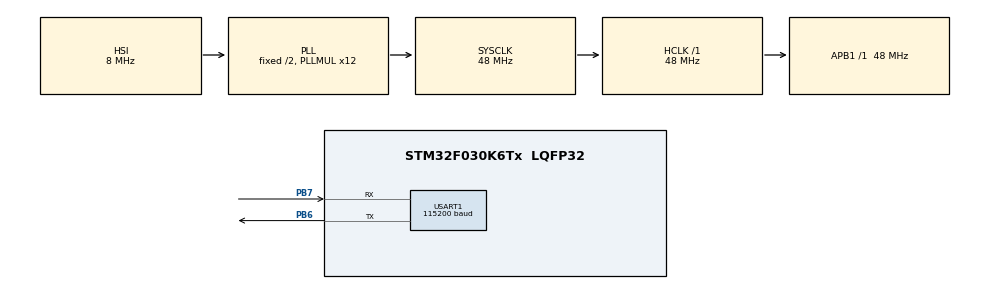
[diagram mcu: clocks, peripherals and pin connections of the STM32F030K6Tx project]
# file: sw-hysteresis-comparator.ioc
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Mcu.Family=STM32F0
Mcu.Name=STM32F030K6Tx
Mcu.Package=LQFP32
PB6.Mode=Asynchronous
PB6.Signal=USART1_TX
PB7.Mode=Asynchronous
PB7.Signal=USART1_RX
ProjectManager.HeapSize=0x200
ProjectManager.StackSize=0x400
ProjectManager.TargetToolchain=MDK-ARM V5
RCC.AHBFreq_Value=48000000
RCC.APB1Freq_Value=48000000
RCC.APB1TimFreq_Value=48000000
RCC.FLatency=FLASH_LATENCY_1
RCC.HCLKFreq_Value=48000000
RCC.PLLMUL=RCC_PLL_MUL12
RCC.SYSCLKFreq_VALUE=48000000
RCC.SYSCLKSource=RCC_SYSCLKSOURCE_PLLCLK
USART1.BaudRate=115200
USART1.VirtualMode-Asynchronous=VM_ASYNC
board=custom

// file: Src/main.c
/* USER CODE BEGIN Header */

/* USER CODE END Header */

#include "main.h"

/* USER CODE BEGIN Includes */
#include "stdio-port-stm32.h"
#include "utility.h"
#include "hysteresis.h"
/* USER CODE END Includes */

UART_HandleTypeDef huart1;

/* USER CODE BEGIN PV */

hysteresis_t hys_cpm;

/* USER CODE END PV */

void SystemClock_Config(void);
static void MX_GPIO_Init(void);
static void MX_USART1_UART_Init(void);

int main(void)
{

  /* MCU Configuration--------------------------------------------------------*/

  /* Reset of all peripherals, Initializes the Flash interface and the Systick. */
  HAL_Init();

  /* Configure the system clock */
  SystemClock_Config();

  /* Initialize all configured peripherals */
  MX_GPIO_Init();
  MX_USART1_UART_Init();
  /* USER CODE BEGIN 2 */
  hysteresis_create(&hys_cpm, 500, 400); /* 500 - compare value, 400 - time delay in ms*/

  /* USER CODE END 2 */

  /* Infinite loop */
  /* USER CODE BEGIN WHILE */
  int32_t signal = 500;
  int32_t noise_signal = 0;
  bool inc_dec = false;

  bool normal_compare;
  uint32_t time;
  uint32_t gen_time;
  uint32_t print_time;
  uint32_t noise_inject_time;
  while (1)
  {
    time = HAL_GetTick();
    /* signal generator */
    if (time - gen_time > 1000)
    {
      gen_time = time;

      if (signal < 400) /* Mininum siganl applitude */
      {
        inc_dec = true;
      }
      if (signal > 600) /* Mininum siganl applitude */
      {
        inc_dec = false;
      }

      if (inc_dec)
      {
        signal += 50;
      }
      else
      {
        signal -= 50;
      }
    }

    /* Noise signal injection */
    if (time - noise_inject_time > 50)
    {
      noise_inject_time = time;
      noise_signal = signal + random(-100, 100);
    }

    /* convetional method data comapare */
    if (noise_signal > 500)
    {
      normal_compare = true;
    }
    else
    {
      normal_compare = false;
    }

    /* Hysteresis comapare */
    hysteresis_compare(&hys_cpm, noise_signal);

    /* print signal */
    if (time - print_time > 50)
    {
      print_time = time;
      printf("$%d %d %d;", noise_signal, normal_compare * 100,
             -110 + hys_cpm.hys_state * 100);
      /* Value add and multiply for shift signal in plot*/
    }
    /* USER CODE END WHILE */

  }
}

void SystemClock_Config(void)
{
  RCC_OscInitTypeDef RCC_OscInitStruct = { 0 };
  RCC_ClkInitTypeDef RCC_ClkInitStruct = { 0 };
  RCC_PeriphCLKInitTypeDef PeriphClkInit = { 0 };

  /**Initializes the CPU, AHB and APB busses clocks
   */
  RCC_OscInitStruct.OscillatorType = RCC_OSCILLATORTYPE_HSI;
  RCC_OscInitStruct.HSIState = RCC_HSI_ON;
  RCC_OscInitStruct.HSICalibrationValue = RCC_HSICALIBRATION_DEFAULT;
  RCC_OscInitStruct.PLL.PLLState = RCC_PLL_ON;
  RCC_OscInitStruct.PLL.PLLSource = RCC_PLLSOURCE_HSI;
  RCC_OscInitStruct.PLL.PLLMUL = RCC_PLL_MUL12;
  RCC_OscInitStruct.PLL.PREDIV = RCC_PREDIV_DIV1;
  if (HAL_RCC_OscConfig(&RCC_OscInitStruct) != HAL_OK)
  {
    Error_Handler();
  }
  /**Initializes the CPU, AHB and APB busses clocks
   */
  RCC_ClkInitStruct.ClockType = RCC_CLOCKTYPE_HCLK | RCC_CLOCKTYPE_SYSCLK
                                | RCC_CLOCKTYPE_PCLK1;
  RCC_ClkInitStruct.SYSCLKSource = RCC_SYSCLKSOURCE_PLLCLK;
  RCC_ClkInitStruct.AHBCLKDivider = RCC_SYSCLK_DIV1;
  RCC_ClkInitStruct.APB1CLKDivider = RCC_HCLK_DIV1;

  if (HAL_RCC_ClockConfig(&RCC_ClkInitStruct, FLASH_LATENCY_1) != HAL_OK)
  {
    Error_Handler();
  }
  PeriphClkInit.PeriphClockSelection = RCC_PERIPHCLK_USART1;
  PeriphClkInit.Usart1ClockSelection = RCC_USART1CLKSOURCE_PCLK1;
  if (HAL_RCCEx_PeriphCLKConfig(&PeriphClkInit) != HAL_OK)
  {
    Error_Handler();
  }
}

static void MX_USART1_UART_Init(void)
{

  huart1.Instance = USART1;
  huart1.Init.BaudRate = 115200;
  huart1.Init.WordLength = UART_WORDLENGTH_8B;
  huart1.Init.StopBits = UART_STOPBITS_1;
  huart1.Init.Parity = UART_PARITY_NONE;
  huart1.Init.Mode = UART_MODE_TX_RX;
  huart1.Init.HwFlowCtl = UART_HWCONTROL_NONE;
  huart1.Init.OverSampling = UART_OVERSAMPLING_16;
  huart1.Init.OneBitSampling = UART_ONE_BIT_SAMPLE_DISABLE;
  huart1.AdvancedInit.AdvFeatureInit = UART_ADVFEATURE_NO_INIT;
  if (HAL_UART_Init(&huart1) != HAL_OK)
  {
    Error_Handler();
  }
}

static void MX_GPIO_Init(void)
{
  /* GPIO Ports Clock Enable */
  __HAL_RCC_GPIOB_CLK_ENABLE();
}

void Error_Handler(void)
{
}

/************************ (C) COPYRIGHT STMicroelectronics *****END OF FILE****/
